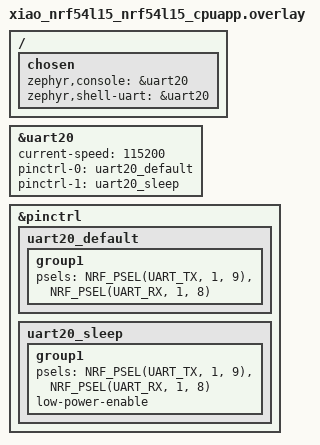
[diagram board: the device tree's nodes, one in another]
// UART20 Configuration for XIAO nRF54L15 USB CDC
// UART20 is connected to the USB CDC interface on pins P1.09 (TX) and P1.08 (RX)

/ {
	chosen {
		zephyr,console = &uart20;
		zephyr,shell-uart = &uart20;
	};
};

&uart20 {
	status = "okay";
	current-speed = <115200>;
	pinctrl-0 = <&uart20_default>;
	pinctrl-1 = <&uart20_sleep>;
	pinctrl-names = "default", "sleep";
};

&pinctrl {
	uart20_default: uart20_default {
		group1 {
			psels = <NRF_PSEL(UART_TX, 1, 9)>,
				<NRF_PSEL(UART_RX, 1, 8)>;
		};
	};

	uart20_sleep: uart20_sleep {
		group1 {
			psels = <NRF_PSEL(UART_TX, 1, 9)>,
				<NRF_PSEL(UART_RX, 1, 8)>;
			low-power-enable;
		};
	};
};

